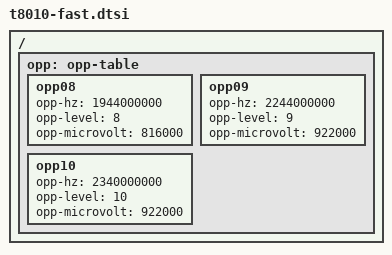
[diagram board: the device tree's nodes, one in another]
// SPDX-License-Identifier: GPL-2.0 OR MIT
/*
 * Apple T8010 "A10" common device tree for non-iPod touch 7 devices
 *
 * Copyright (c) 2024, Nick Chan <towinchenmi@gmail.com>
 */

#include "t8010.dtsi"

/ {
	opp: opp-table {
		opp08 {
			opp-hz = /bits/ 64 <1944000000>;
			opp-level = <8>;
			opp-microvolt = <816000>;
		};

		opp09 {
			opp-hz = /bits/ 64 <2244000000>;
			opp-level = <9>;
			opp-microvolt = <922000>;
		};

		opp10 {
			opp-hz = /bits/ 64 <2340000000>;
			opp-level = <10>;
			opp-microvolt = <922000>;
		};
	};
};
